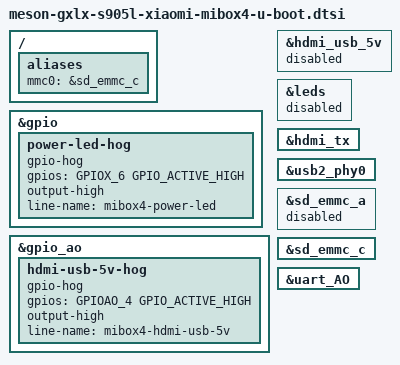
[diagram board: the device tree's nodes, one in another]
// SPDX-License-Identifier: (GPL-2.0+ OR MIT)
// Copyright (c) 2026 YuChia-Kan <mail@raspberrykan.dev>

#include "meson-gxl-u-boot.dtsi"

/ {
	aliases {
		mmc0 = &sd_emmc_c;
		/delete-property/ mmc1;
		/delete-property/ mmc2;
	};
};

&gpio {
	power-led-hog {
		gpio-hog;
		gpios = <GPIOX_6 GPIO_ACTIVE_HIGH>;
		output-high;
		line-name = "mibox4-power-led";
	};
};

&gpio_ao {
	hdmi-usb-5v-hog {
		gpio-hog;
		gpios = <GPIOAO_4 GPIO_ACTIVE_HIGH>;
		output-high;
		line-name = "mibox4-hdmi-usb-5v";
	};
};

&hdmi_usb_5v {
	status = "disabled";
};

&leds {
	status = "disabled";
};

&hdmi_tx {
	/delete-property/ hdmi-supply;
};

&usb2_phy0 {
	/delete-property/ phy-supply;
};

&sd_emmc_a {
	status = "disabled";
};

&sd_emmc_c {
	bootph-all;
};

&uart_AO {
	bootph-all;
};
